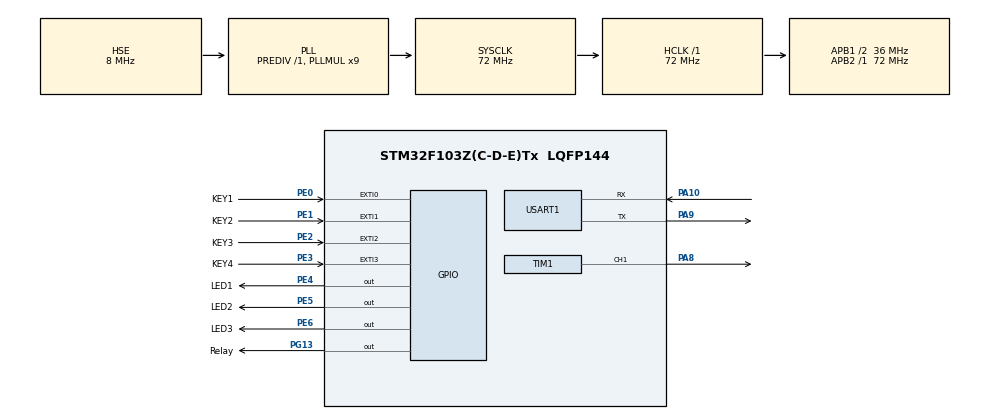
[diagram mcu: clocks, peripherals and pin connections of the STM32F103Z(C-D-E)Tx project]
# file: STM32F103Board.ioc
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Mcu.Family=STM32F1
Mcu.Name=STM32F103Z(C-D-E)Tx
Mcu.Package=LQFP144
NVIC.EXTI0_IRQn=true\:1\:0\:true\:false\:true\:true\:true\:true
NVIC.EXTI1_IRQn=true\:1\:1\:true\:false\:true\:true\:true\:true
NVIC.EXTI2_IRQn=true\:1\:2\:true\:false\:true\:true\:true\:true
NVIC.EXTI3_IRQn=true\:1\:3\:true\:false\:true\:true\:true\:true
NVIC.PriorityGroup=NVIC_PRIORITYGROUP_2
NVIC.TIM6_IRQn=true\:0\:1\:true\:false\:true\:true\:true\:true
NVIC.USART1_IRQn=true\:0\:0\:true\:false\:true\:true\:true\:true
OSC_IN.Mode=HSE-External-Oscillator
OSC_IN.Signal=RCC_OSC_IN
OSC_OUT.Mode=HSE-External-Oscillator
OSC_OUT.Signal=RCC_OSC_OUT
PA10.Mode=Asynchronous
PA10.Signal=USART1_RX
PA13.Mode=Serial_Wire
PA13.Signal=SYS_JTMS-SWDIO
PA14.Mode=Serial_Wire
PA14.Signal=SYS_JTCK-SWCLK
PA8.Signal=S_TIM1_CH1
PA9.Mode=Asynchronous
PA9.Signal=USART1_TX
PE0.GPIO_Label=KEY1
PE0.GPIO_ModeDefaultEXTI=GPIO_MODE_IT_FALLING
PE0.Signal=GPXTI0
PE1.GPIO_Label=KEY2
PE1.GPIO_ModeDefaultEXTI=GPIO_MODE_IT_FALLING
PE1.Signal=GPXTI1
PE2.GPIO_Label=KEY3
PE2.GPIO_ModeDefaultEXTI=GPIO_MODE_IT_FALLING
PE2.Signal=GPXTI2
PE3.GPIO_Label=KEY4
PE3.GPIO_ModeDefaultEXTI=GPIO_MODE_IT_FALLING
PE3.Signal=GPXTI3
PE4.GPIO_Label=LED1
PE4.GPIO_Speed=GPIO_SPEED_FREQ_LOW
PE4.PinState=GPIO_PIN_RESET
PE4.Signal=GPIO_Output
PE5.GPIO_Label=LED2
PE5.PinState=GPIO_PIN_RESET
PE5.Signal=GPIO_Output
PE6.GPIO_Label=LED3
PE6.PinState=GPIO_PIN_RESET
PE6.Signal=GPIO_Output
PG13.GPIO_Label=Relay
PG13.Signal=GPIO_Output
ProjectManager.HeapSize=0x200
ProjectManager.StackSize=0x400
ProjectManager.TargetToolchain=MDK-ARM V5.27
RCC.AHBFreq_Value=72000000
RCC.APB1CLKDivider=RCC_HCLK_DIV2
RCC.APB1Freq_Value=36000000
RCC.APB1TimFreq_Value=72000000
RCC.APB2Freq_Value=72000000
RCC.APB2TimFreq_Value=72000000
RCC.EnbaleCSS=true
RCC.HCLKFreq_Value=72000000
RCC.PLLMUL=RCC_PLL_MUL9
RCC.PLLSourceVirtual=RCC_PLLSOURCE_HSE
RCC.SYSCLKFreq_VALUE=72000000
RCC.SYSCLKSource=RCC_SYSCLKSOURCE_PLLCLK
RCC.USBFreq_Value=72000000
SH.S_TIM1_CH1.0=TIM1_CH1,PWM Generation1 CH1
TIM1.AutoReloadPreload=TIM_AUTORELOAD_PRELOAD_ENABLE
TIM1.Channel-PWM\ Generation1\ CH1=TIM_CHANNEL_1
TIM1.Period=1000000/10000
TIM1.Prescaler=71
TIM1.Pulse-PWM\ Generation1\ CH1=50
TIM6.AutoReloadPreload=TIM_AUTORELOAD_PRELOAD_ENABLE
TIM6.Period=1000000/200
TIM6.Prescaler=72-1
TIM7.AutoReloadPreload=TIM_AUTORELOAD_PRELOAD_ENABLE
TIM7.Prescaler=71
USART1.VirtualMode=VM_ASYNC
VP_TIM1_VS_ClockSourceINT.Mode=Internal
VP_TIM6_VS_ClockSourceINT.Mode=Enable_Timer
VP_TIM7_VS_ClockSourceINT.Mode=Enable_Timer
board=custom

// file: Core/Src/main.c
/* USER CODE BEGIN Header */
/**
  ******************************************************************************
  * @file           : main.c
  * @brief          : Main program body
  ******************************************************************************
  * @attention
  *
  * <h2><center>&copy; Copyright (c) 2022 STMicroelectronics.
  * All rights reserved.</center></h2>
  *
  * This software component is licensed by ST under BSD 3-Clause license,
  * the "License"; You may not use this file except in compliance with the
  * License. You may obtain a copy of the License at:
  *                        opensource.org/licenses/BSD-3-Clause
  *
  ******************************************************************************
  */
/* USER CODE END Header */
#include "main.h"
#include "tim.h"
#include "usart.h"
#include "gpio.h"

/* USER CODE BEGIN Includes */
#include "MyApplication.h"

/* USER CODE END Includes */

void SystemClock_Config(void);

/* USER CODE BEGIN 0 */

void delay_us(uint32_t nus)  // nus<65536
{
	__HAL_TIM_SET_COUNTER(&htim7, 0);
	HAL_TIM_Base_Start(&htim1);
	while (__HAL_TIM_GET_COUNTER(&htim7) < nus)
	{
	}
	HAL_TIM_Base_Stop(&htim7);
//	__HAL_TIM_DISABLE(&htim1);
}

/* USER CODE END 0 */

int main(void)
{

  /* MCU Configuration--------------------------------------------------------*/

  /* Reset of all peripherals, Initializes the Flash interface and the Systick. */
  HAL_Init();

  /* Configure the system clock */
  SystemClock_Config();

  /* Initialize all configured peripherals */
  MX_GPIO_Init();
  MX_USART1_UART_Init();
  MX_TIM6_Init();
  MX_TIM7_Init();
  MX_TIM1_Init();
  /* USER CODE BEGIN 2 */

	HAL_UART_Receive_IT(&huart1,UART_TMP,1);//开启UART1接收中断
	HAL_TIM_Base_Start_IT(&htim6); //启动定时器6
	HAL_TIM_Base_Start(&htim1);

  /* USER CODE END 2 */

  /* Infinite loop */
  /* USER CODE BEGIN WHILE */
  while (1)
  {
	  System_Run();
//		HAL_Delay(100);
//		LED_Flip(LED2);
//		delay_us(50000);
    /* USER CODE END WHILE */

  }
}

void SystemClock_Config(void)
{
  RCC_OscInitTypeDef RCC_OscInitStruct = {0};
  RCC_ClkInitTypeDef RCC_ClkInitStruct = {0};

  /** Initializes the RCC Oscillators according to the specified parameters
  * in the RCC_OscInitTypeDef structure.
  */
  RCC_OscInitStruct.OscillatorType = RCC_OSCILLATORTYPE_HSE;
  RCC_OscInitStruct.HSEState = RCC_HSE_ON;
  RCC_OscInitStruct.HSEPredivValue = RCC_HSE_PREDIV_DIV1;
  RCC_OscInitStruct.HSIState = RCC_HSI_ON;
  RCC_OscInitStruct.PLL.PLLState = RCC_PLL_ON;
  RCC_OscInitStruct.PLL.PLLSource = RCC_PLLSOURCE_HSE;
  RCC_OscInitStruct.PLL.PLLMUL = RCC_PLL_MUL9;
  if (HAL_RCC_OscConfig(&RCC_OscInitStruct) != HAL_OK)
  {
    Error_Handler();
  }

  /** Initializes the CPU, AHB and APB buses clocks
  */
  RCC_ClkInitStruct.ClockType = RCC_CLOCKTYPE_HCLK|RCC_CLOCKTYPE_SYSCLK
                              |RCC_CLOCKTYPE_PCLK1|RCC_CLOCKTYPE_PCLK2;
  RCC_ClkInitStruct.SYSCLKSource = RCC_SYSCLKSOURCE_PLLCLK;
  RCC_ClkInitStruct.AHBCLKDivider = RCC_SYSCLK_DIV1;
  RCC_ClkInitStruct.APB1CLKDivider = RCC_HCLK_DIV2;
  RCC_ClkInitStruct.APB2CLKDivider = RCC_HCLK_DIV1;

  if (HAL_RCC_ClockConfig(&RCC_ClkInitStruct, FLASH_LATENCY_2) != HAL_OK)
  {
    Error_Handler();
  }

  /** Enables the Clock Security System
  */
  HAL_RCC_EnableCSS();
}

void Error_Handler(void)
{
  __disable_irq();
  while (1)
  {
  }
}
